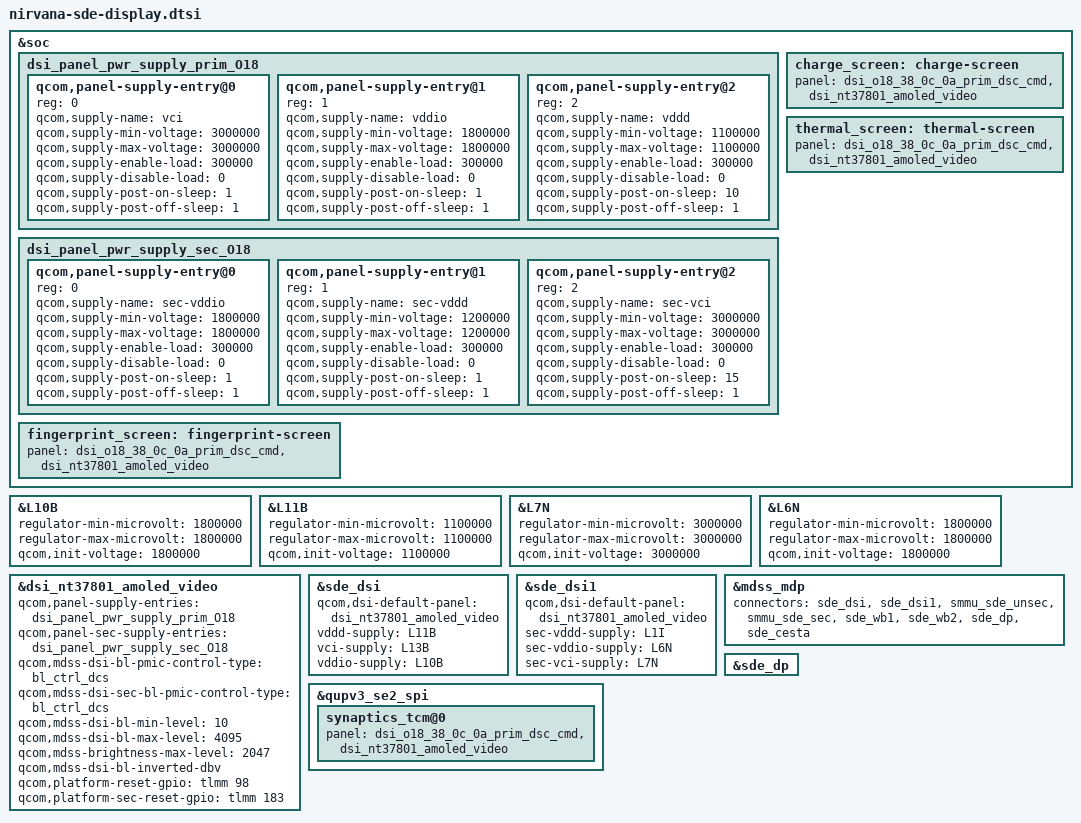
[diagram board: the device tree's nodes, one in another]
#include "sun-sde-display.dtsi"
#include "dsi-panel-o18-38-0c-0a-prim-dsc-cmd.dtsi"
#include "dsi-panel-o18-42-02-0a-sec-dsc-cmd.dtsi"
#include "dsi-panel-nt37801-dsc-wqhd-plus-video.dtsi"

&soc {
	dsi_panel_pwr_supply_prim_O18: dsi_panel_pwr_supply_prim_O18 {
		qcom,panel-supply-entry@0 {
			reg = <0>;
			qcom,supply-name = "vci";
			qcom,supply-min-voltage = <3000000>;
			qcom,supply-max-voltage = <3000000>;
			qcom,supply-enable-load = <300000>;
			qcom,supply-disable-load = <0>;
			qcom,supply-post-on-sleep = <1>;
			qcom,supply-post-off-sleep = <1>;
		};
		qcom,panel-supply-entry@1 {
			reg = <1>;
			qcom,supply-name = "vddio";
			qcom,supply-min-voltage = <1800000>;
			qcom,supply-max-voltage = <1800000>;
			qcom,supply-enable-load = <300000>;
			qcom,supply-disable-load = <0>;
			qcom,supply-post-on-sleep = <1>;
			qcom,supply-post-off-sleep = <1>;
		};
		qcom,panel-supply-entry@2 {
			reg = <2>;
			qcom,supply-name = "vddd";
			qcom,supply-min-voltage = <1100000>;
			qcom,supply-max-voltage = <1100000>;
			qcom,supply-enable-load = <300000>;
			qcom,supply-disable-load = <0>;
			qcom,supply-post-on-sleep = <10>;
			qcom,supply-post-off-sleep = <1>;
		};
	};

	dsi_panel_pwr_supply_sec_O18: dsi_panel_pwr_supply_sec_O18 {
		qcom,panel-supply-entry@0 {
			reg = <0>;
			qcom,supply-name = "sec-vddio";
			qcom,supply-min-voltage = <1800000>;
			qcom,supply-max-voltage = <1800000>;
			qcom,supply-enable-load = <300000>;
			qcom,supply-disable-load = <0>;
			qcom,supply-post-on-sleep = <1>;
			qcom,supply-post-off-sleep = <1>;
		};
		qcom,panel-supply-entry@1 {
			reg = <1>;
			qcom,supply-name = "sec-vddd";
			qcom,supply-min-voltage = <1200000>;
			qcom,supply-max-voltage = <1200000>;
			qcom,supply-enable-load = <300000>;
			qcom,supply-disable-load = <0>;
			qcom,supply-post-on-sleep = <1>;
			qcom,supply-post-off-sleep = <1>;
		};
		qcom,panel-supply-entry@2 {
			reg = <2>;
			qcom,supply-name = "sec-vci";
			qcom,supply-min-voltage = <3000000>;
			qcom,supply-max-voltage = <3000000>;
			qcom,supply-enable-load = <300000>;
			qcom,supply-disable-load = <0>;
			qcom,supply-post-on-sleep = <15>;
			qcom,supply-post-off-sleep = <1>;
		};
	};
};

&L10B {
	regulator-min-microvolt = <1800000>;
	regulator-max-microvolt = <1800000>;
	qcom,init-voltage = <1800000>;
};

&L11B {
	regulator-min-microvolt = <1100000>;
	regulator-max-microvolt = <1100000>;
	qcom,init-voltage = <1100000>;
};

&L7N {
	regulator-min-microvolt = <3000000>;
	regulator-max-microvolt = <3000000>;
	qcom,init-voltage = <3000000>;
};

&L6N {
	regulator-min-microvolt = <1800000>;
	regulator-max-microvolt = <1800000>;
	qcom,init-voltage = <1800000>;
};

&dsi_nt37801_amoled_video {
	qcom,panel-supply-entries = <&dsi_panel_pwr_supply_prim_O18>;
	qcom,panel-sec-supply-entries = <&dsi_panel_pwr_supply_sec_O18>;
	qcom,mdss-dsi-bl-pmic-control-type = "bl_ctrl_dcs";
	qcom,mdss-dsi-sec-bl-pmic-control-type = "bl_ctrl_dcs";
	qcom,mdss-dsi-bl-min-level = <10>;
	qcom,mdss-dsi-bl-max-level = <4095>;
	qcom,mdss-brightness-max-level = <2047>;
	qcom,mdss-dsi-bl-inverted-dbv;
	qcom,platform-reset-gpio = <&tlmm 98 0>;
	qcom,platform-sec-reset-gpio = <&tlmm 183 0>;
};

&sde_dsi {
	qcom,dsi-default-panel = <&dsi_nt37801_amoled_video>;
	vddd-supply = <&L11B>;
	vci-supply = <&L13B>;
	vddio-supply = <&L10B>;
};

&sde_dsi1 {
	qcom,dsi-default-panel = <&dsi_nt37801_amoled_video>;
	sec-vddd-supply = <&L1I>;
	sec-vddio-supply = <&L6N>;
	sec-vci-supply = <&L7N>;
};

&mdss_mdp {
	connectors = <&sde_dsi &sde_dsi1 &smmu_sde_unsec &smmu_sde_sec &sde_wb1 &sde_wb2 &sde_dp &sde_cesta>;
};

&sde_dp {
	status = "ok";
};

&qupv3_se2_spi {
	synaptics_tcm@0 {
		panel = <&dsi_o18_38_0c_0a_prim_dsc_cmd
			&dsi_nt37801_amoled_video>;
	};
};

&soc {
	charge_screen: charge-screen {
		panel  = <&dsi_o18_38_0c_0a_prim_dsc_cmd
			&dsi_nt37801_amoled_video>;
	};
};

&soc {
	thermal_screen: thermal-screen {
		panel = <&dsi_o18_38_0c_0a_prim_dsc_cmd
			&dsi_nt37801_amoled_video>;
	};
	fingerprint_screen: fingerprint-screen {
		panel = <&dsi_o18_38_0c_0a_prim_dsc_cmd
			&dsi_nt37801_amoled_video>;
	};
};
